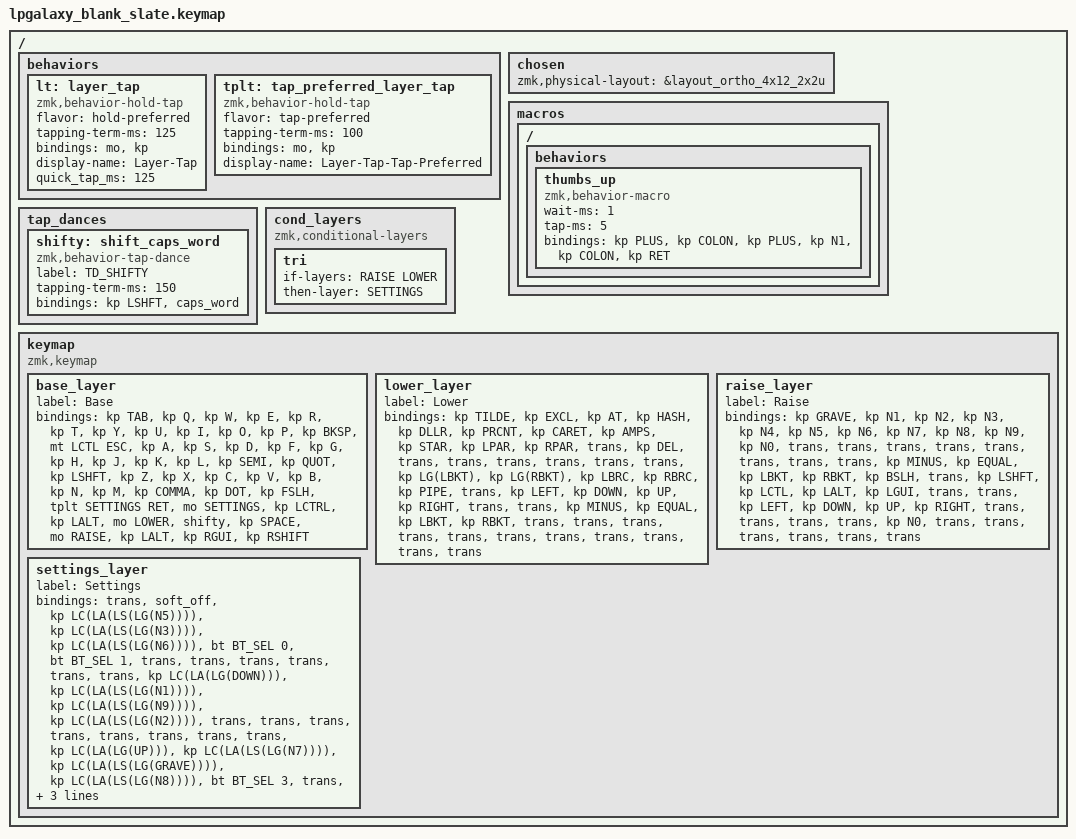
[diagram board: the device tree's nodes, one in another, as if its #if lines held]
/*
 * Copyright (c) 2022 Pete Johanson
 *
 * SPDX-License-Identifier: MIT
 */

#include <behaviors.dtsi>
#include <dt-bindings/zmk/keys.h>
#include <dt-bindings/zmk/bt.h>
#include <dt-bindings/zmk/outputs.h>

#include <dt-bindings/zmk/behaviors.h>

/ {
    behaviors {
        lt: layer_tap {
            compatible = "zmk,behavior-hold-tap";
            #binding-cells = <2>;
            flavor = "hold-preferred";
            tapping-term-ms = <125>;
            bindings = <&mo>, <&kp>;
            display-name = "Layer-Tap";
        };
    };
};

/ {
    behaviors {
        tplt: tap_preferred_layer_tap {
            compatible = "zmk,behavior-hold-tap";
            #binding-cells = <2>;
            flavor = "tap-preferred";
            tapping-term-ms = <100>;
            bindings = <&mo>, <&kp>;
            display-name = "Layer-Tap-Tap-Preferred";
        };
    };
};

// #define TBLE_ORTHO   1
#define TBLE_MIT     1
// #define TBLE_DUAL_2U 1

#define LOWER 1
#define RAISE 2
#define SETTINGS 3

// Using layer taps on thumbs, having quick tap as well helps w/ repeating space/backspace
&lt { quick_tap_ms = <125>; };

#define BT(n) BT_SEL n

/ {
    chosen {
       zmk,physical-layout =
#ifdef TBLE_DUAL_2U
                       &layout_ortho_4x12_2x2u;
#elif defined(TBLE_MIT)
                       &layout_ortho_4x12_1x2u;
#else
                       &layout_ortho_4x12_all1u;
#endif
    };

    macros {
      ZMK_MACRO(thumbs_up,
		wait-ms = <1>;
		tap-ms = <5>;
                bindings = <&kp PLUS &kp COLON &kp PLUS &kp N1 &kp COLON &kp RET>;
		)
    };
    
    tap_dances {
    	shifty: shift_caps_word {
		compatible = "zmk,behavior-tap-dance";
		label = "TD_SHIFTY";
		#binding-cells = <0>;
		tapping-term-ms = <150>;
		bindings = <&kp LSHFT>, <&caps_word>;
	};
    };

// Conditional layer only when we have less thumb keys
#ifdef TBLE_DUAL_2U
    cond_layers {
        compatible = "zmk,conditional-layers";
	tri {
	    if-layers = <RAISE LOWER>;
	    then-layer = <SETTINGS>;
        };
    };
#endif

    keymap {
        compatible = "zmk,keymap";

        base_layer {
            label = "Base";
            bindings = <
 &kp TAB    &kp Q      &kp W      &kp E       &kp R          &kp T          &kp Y            &kp U          &kp I       &kp O      &kp P         &kp BKSP
 &mt LCTL ESC  &kp A   &kp S      &kp D       &kp F          &kp G          &kp H            &kp J          &kp K       &kp L      &kp SEMI      &kp QUOT
 &kp LSHFT  &kp Z      &kp X      &kp C       &kp V          &kp B          &kp N            &kp M          &kp COMMA   &kp DOT    &kp FSLH      &tplt SETTINGS RET
#ifdef TBLE_DUAL_2U
 &mo SETTINGS  &kp LCTRL  &kp LALT   &mo LOWER         &shifty                        &kp SPACE                &mo RAISE   &kp LALT   &kp RGUI      &kp RSHIFT
#elif defined(TBLE_MIT)
 &kp LC(LA(LS(LG(N4))))  &kp LCTRL  &kp LALT  &kp LGUI  &lt LOWER KP_MINUS  &kp SPACE  &lt RAISE KP_PLUS  &kp LEFT    &kp DOWN     &kp UP      &kp RIGHT
#else
 &mo SETTINGS  &kp LCTRL  &kp LGUI  &kp LALT    &mo LOWER      &kp SPACE      &kp RET          &mo RAISE      &kp LEFT    &kp UP     &kp DOWN      &kp RIGHT
#endif
            >;
        };

        lower_layer {
            label = "Lower";
            bindings = <
&kp TILDE  &kp EXCL   &kp AT     &kp HASH    &kp DLLR        &kp PRCNT    &kp CARET  &kp AMPS      &kp STAR     &kp LPAR   &kp RPAR   &trans
&kp DEL    &trans     &trans     &trans      &trans          &trans       &trans     &kp LG(LBKT)  &kp LG(RBKT) &kp LBRC   &kp RBRC   &kp PIPE
&trans     &kp LEFT   &kp DOWN   &kp UP      &kp RIGHT       &trans       &trans     &kp MINUS     &kp EQUAL    &kp LBKT   &kp RBKT   &trans
#ifdef TBLE_DUAL_2U
&trans  &trans        &trans     &trans              &trans                    &trans       &trans         &trans &trans &trans
#elif defined(TBLE_MIT)
&trans  &trans        &trans     &trans      &trans                &trans             &mo SETTINGS      &trans   &trans &trans &trans
#else
&trans  &trans        &trans     &trans      &trans          &trans       &trans    &trans  &trans         &trans &trans &trans
#endif
            >;
        };

        raise_layer {
            label = "Raise";
            bindings = <
&kp GRAVE  &kp N1     &kp N2 &kp N3 &kp N4    &kp N5      &kp N6        &kp N7     &kp N8      &kp N9       &kp N0     &trans
&trans     &trans     &trans &trans &trans    &trans      &trans        &kp MINUS  &kp EQUAL   &kp LBKT     &kp RBKT   &kp BSLH
&trans     &kp LSHFT  &kp LCTL &kp LALT &kp LGUI   &trans &trans        &kp LEFT   &kp DOWN    &kp UP       &kp RIGHT  &trans
#ifdef TBLE_DUAL_2U
&trans  &trans       &trans     &kp N0              &trans                 &trans            &trans         &trans &trans &trans
#elif defined(TBLE_MIT)
&trans  &trans       &trans     &trans      &mo SETTINGS     &trans     &trans  &kp C_PLAY_PAUSE &kp C_VOLUME_DOWN &kp C_MUTE &kp C_VOLUME_UP
#else
&trans  &trans       &trans     &kp N0      &trans    &none         &none     &kp ESC        &kp DEL      &trans &trans &trans
#endif
            >;
        };

        settings_layer {
            label = "Settings";
            bindings = <
&trans  &soft_off  &kp LC(LA(LS(LG(N5)))) &kp LC(LA(LS(LG(N3)))) &kp LC(LA(LS(LG(N6))))              &bt BT_SEL 0 &bt BT_SEL 1    &trans &trans &trans &trans &trans 
&trans  &kp LC(LA(LG(DOWN))) &kp LC(LA(LS(LG(N1)))) &kp LC(LA(LS(LG(N9)))) &kp LC(LA(LS(LG(N2))))    &trans       &trans          &trans &trans &trans &trans &trans 
&trans  &kp LC(LA(LG(UP)))   &kp LC(LA(LS(LG(N7)))) &kp LC(LA(LS(LG(GRAVE)))) &kp LC(LA(LS(LG(N8)))) &bt BT_SEL 3 &trans          &trans &trans &trans &trans &trans
#ifdef TBLE_DUAL_2U
&trans &trans        &trans     &kp RPAR                &trans                    &trans       &trans         &trans &trans &bootloader
#elif defined(TBLE_MIT)
&bt BT_CLR &trans &trans &trans &trans &trans &trans &trans &trans &trans &bootloader 
#else
&trans &trans        &trans     &kp RPAR        &trans          &trans       &trans    &trans  &trans         &trans &trans &studio_unlock
#endif
            >;
        };

    };
};
